# A31G33x register map
Vendor: VENDOR ABOV Semiconductor Co., Ltd.; Series: A31G33x; File version: 1.0
CPU: CM0+ r0p1, little endian, no MPU, no FPU, VTOR, 2 interrupt priority bits
Registers are 32-bit, read-only, no defined reset value unless marked. A register's access mark holds for its fields unless they carry their own. Offsets are from the block's base; [hi:lo] are bit positions; {n}, {i} and the like mark numbered series.

## DMACn — DMA Controller Channel n
Base 0x51000000
Same registers: DMAC0 0x40005D00, DMAC1 0x40005D20, DMAC2 0x40005D40, DMAC3 0x40005D60
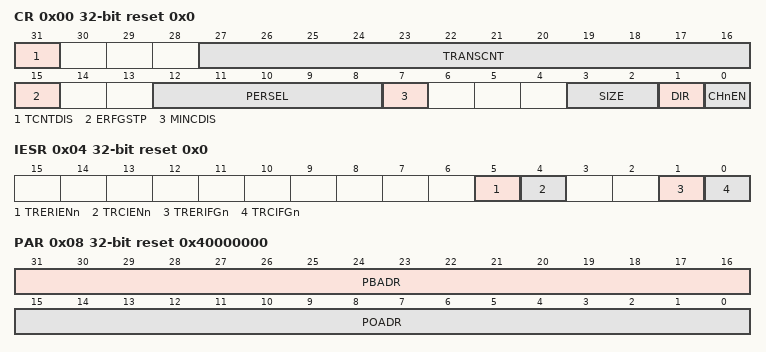
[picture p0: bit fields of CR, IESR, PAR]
0x00 CR rw reset 0x0 — DMA Channel n Control Register
  [31] TCNTDIS — Transfer Counter Decrement Disable
    0=Enable transfer counter decrement; 1=Disable transfer counter decrement
  [27:16] TRANSCNT — The number of times to transfer
  [15] ERFGSTP — Error Flag Stop
    0=Disable DMA stop function by an error of peripheral; 1=Enable DMA stop function by an error of peripheral
  [12:8] PERSEL — Peripheral Selection
    0=Idle (Channel idle); 1=ADC; 2=SPI0Rx; 3=SPI0Tx; 4=SPI1Rx; 5=SPI1Tx; 6=USART10Rx; 7=USART10Tx; 8=I2C0Rx; 9=I2C0Tx; 10=I2C1Rx; 11=I2C1Tx; 12=USART11Rx; 13=USART11Tx; 14=USART12Rx; 15=USART12Tx; 16=USART13Rx; 17=USART13Tx; 18=I2C2Rx; 19=I2C2Tx
  [7] MINCDIS — Memory Increment Disable
    0=Enable memory increment; 1=Disable memory increment
  [3:2] SIZE — Transfer Size Selection
    0=8 bits; 1=16 bits; 2=32 bits
  [1] DIR — Transfer Direction
    0=MemToPeri (Transfer is from memory to peripheral.); 1=PeriToMem (Transfer is from peripheral to memory.)
  [0] CHnEN — DMA Channel Enable
    0=Disable channel n; 1=Enable channel n
0x04 IESR rw reset 0x0 — DMA Channel n Interrupt Enable and Status Register
  [5] TRERIENn — Transfer Error Interrupt Enable
    0=Disable transfer error interrupt; 1=Enable transfer error interrupt
  [4] TRCIENn — Transfer Complete Interrupt Enable
    0=Disable transfer complete interrupt; 1=Enable transfer complete interrupt
  [1] TRERIFGn — Transfer Error Interrupt Flag
    0=No request occurred; 1=Request occurred
  [0] TRCIFGn — Transfer Complete Interrupt Flag
    0=No request occurred; 1=Request occurred
0x08 PAR rw reset 0x40000000 — DMA Channel n Peripheral Address Register
  [31:16] PBADR — Peripheral Base Address
  [15:0] POADR — Peripheral Offset Address
0x0C MAR rw reset 0x20000000 — DMA Channel n Memory Address Register
  [31:0] MAR — Memory Address

## ADC — High Speed 12 Bit A/D Converter
Base 0x40003000
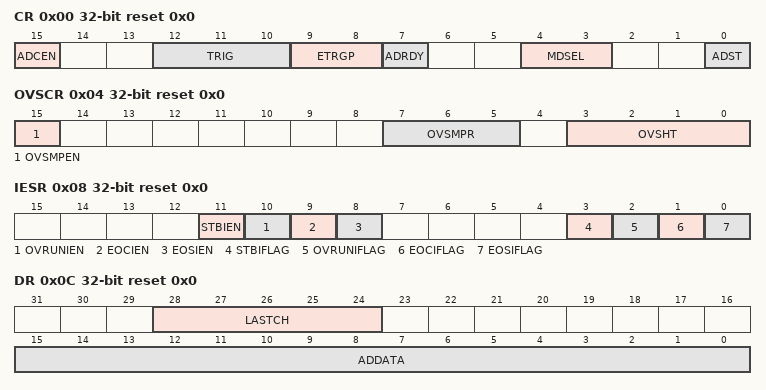
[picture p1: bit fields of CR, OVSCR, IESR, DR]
0x00 CR rw reset 0x0 — A/D Converter Control Register
  [15] ADCEN — ADC Module Enable
    0=Disable ADC Module Operation; 1=Enable ADC Module Operation
  [12:10] TRIG — ADC Trigger Signal Selection
    0=ADST (Select ADST.); {v}=TIMER{v+9} (Timer {v+9} Trigger Signals) (v=1..6); 7=ADTRG (External ADC Trigger Input)
  [9:8] ETRGP — ADC External Trigger Input Polarity Selection
    0=Disable ADC external trigger function; 1=FallingEdge (Trigger on falling edge); 2=RisingEdge (Trigger on rising edge); 3=BothEdge (Trigger on both of falling and rising edge)
  [7] ADRDY — ADC Conversion Ready
    0=Stop subsequent steps; 1=Ready to convert
  [4:3] MDSEL — ADC Conversion Mode Selection
    0=Single Conversion Mode; 1=Sequential Conversion Mode; 2=Continuous Conversion Mode
  [0] ADST — ADC Conversion Start
    0=NoEffect; 1=Start (Trigger signal generation for conversion start.)
0x04 OVSCR rw reset 0x0 — A/D Converter Oversampling Control Register
  [15] OVSMPEN — Oversampling Enable
    0=Disable oversampling; 1=Enable oversampling
  [7:5] OVSMPR — Oversampling Ratio Selection
  [3:0] OVSHT — Oversampling Data Shift
    0=NoShift; {v}=ShiftRight{v}Bit (v=1..8)
0x08 IESR rw reset 0x0 — A/D Converter Interrupt Enable and Status Register
  [11] STBIEN — ADC Stabilization Interrupt Enable
    0=Disable stabilization interrupt; 1=Enable stabilization interrupt
  [10] OVRUNIEN — ADC Data Overrun Interrupt Enable
    0=Disable overrun interrupt; 1=Enable overrun interrupt
  [9] EOCIEN — ADC End of Conversion Interrupt Enable
    0=Disable end of conversion interrupt; 1=Enable end of conversion interrupt
  [8] EOSIEN — ADC End of Sequence Interrupt Enable
    0=Disable end of sequence interrupt; 1=Enable end of sequence interrupt
  [3] STBIFLAG — ADC Stabilization Interrupt Flag
    0=No request occurred; 1=Request occurred
  [2] OVRUNIFLAG — ADC Data Overrun Interrupt Flag
    0=No request occurred; 1=Request occurred
  [1] EOCIFLAG — ADC End of Conversion Interrupt Flag
    0=No request occurred; 1=Request occurred
  [0] EOSIFLAG — ADC End of Sequence Interrupt Flag
    0=No request occurred; 1=Request occurred
0x0C DR reset 0x0 (reset mask 0xFFFF0000) — A/D Converter Data Register
  [28:24] LASTCH — ADC Last Conversion Channel Numbe
  [15:0] ADDATA — A/D Converter Result Data
0x10 PREDR rw reset 0x0 — A/D Converter Prescaler Data Register
  [6:0] PRED — A/D Converter Prescaler Data
0x14 SAMR rw reset 0x0 — A/D Converter Sampling Time Register
  [4:0] SAMCK — Sampling Cycles for Sample/Hold Circuit
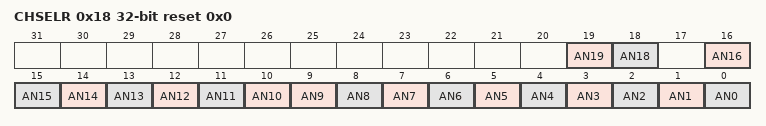
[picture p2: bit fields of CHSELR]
0x18 CHSELR rw reset 0x0 — A/D Converter Channel Selection Register
  [all] fields
    0=NotSelected (ANx is not selected for conversion); 1=Selected (ANx is selected for conversion)
  [19] AN19 — AN19(BGR) Channel Selection
  [18] AN18 — AN18(AVDD) Channel Selection
  [16] AN16 — AN16(AVSS) Channel Selection
  [n] AN{n} (n=11..15) — AN{n} Channel Selection
  [10] AN10 — AN1 Channel Selection
  [n] AN{n} (n=0..9) — AN{n} Channel Selection
